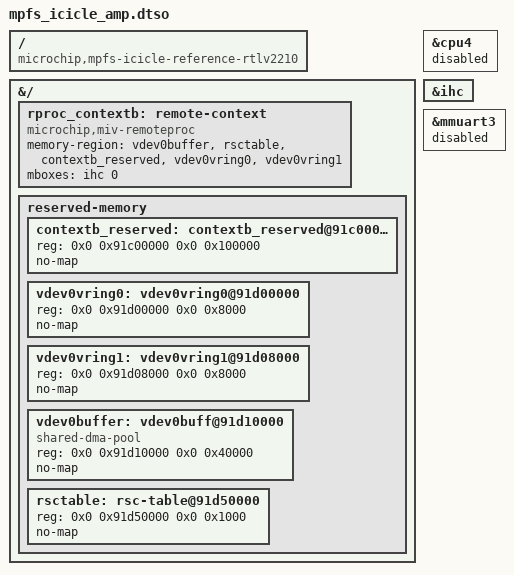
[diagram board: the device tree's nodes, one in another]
// SPDX-License-Identifier: (GPL-2.0+ OR MIT)
/*
 * Device Tree Overlay Example for Asymmetric Multiprocessing (AMP)
 *
 * Copyright (C) 2022 Microchip Technology Inc. and its subsidiaries.
 * Author: Valentina Fernandez <valentina.fernandezalanis@microchip.com>
 *
 */

/dts-v1/;
/plugin/;

/ {
	compatible = "microchip,mpfs-icicle-reference-rtlv2210", "microchip,mpfs-icicle-kit", "microchip,mpfs";
};

&{/} {
	rproc_contextb: remote-context {
		compatible = "microchip,miv-remoteproc";
		memory-region = <&vdev0buffer>, <&rsctable>,
				<&contextb_reserved>, <&vdev0vring0>,
				<&vdev0vring1>;
		mboxes= <&ihc 0>;
		status = "okay";
	};

	reserved-memory {

		#address-cells = <2>;
		#size-cells = <2>;

		contextb_reserved: contextb_reserved@91c00000 {
			reg = <0x0 0x91c00000 0x0 0x100000>;
			no-map;
		};

		vdev0vring0: vdev0vring0@91d00000 {
			reg = <0x0 0x91d00000 0x0 0x8000>;
			no-map;
		};

		vdev0vring1: vdev0vring1@91d08000 {
			reg = <0x0 0x91d08000 0x0 0x8000>;
			no-map;
		};

		vdev0buffer: vdev0buff@91d10000 {
			compatible = "shared-dma-pool";
			reg = <0x0 0x91d10000 0x0 0x40000>;
			no-map;
		};

		rsctable: rsc-table@91d50000 {
			reg = <0x0 0x91d50000 0x0 0x1000>;
			no-map;
		};
	};
};

&cpu4 {
	status = "disabled"; // in use by context b
};

&ihc {
	status = "okay";
};

&mmuart3 {
	status = "disabled"; // in use by context b
};

